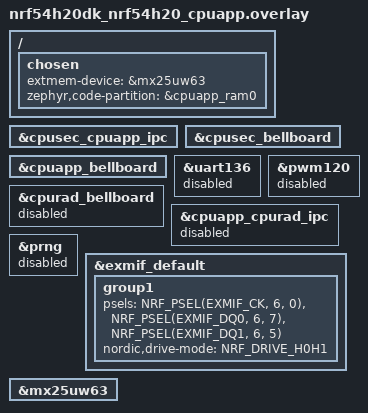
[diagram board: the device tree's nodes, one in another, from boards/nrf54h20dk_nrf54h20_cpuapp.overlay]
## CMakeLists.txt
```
#
# Copyright (c) 2024 Nordic Semiconductor ASA
#
# SPDX-License-Identifier: LicenseRef-Nordic-5-Clause
#

cmake_minimum_required(VERSION 3.20.0)

find_package(Zephyr REQUIRED HINTS $ENV{ZEPHYR_BASE})
project(flash_companion)

target_sources(app PRIVATE src/main.c)
```

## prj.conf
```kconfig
#
# Copyright (c) 2024 Nordic Semiconductor ASA
#
# SPDX-License-Identifier: LicenseRef-Nordic-5-Clause
#

# Minimal scheduler configuration
CONFIG_NUM_PREEMPT_PRIORITIES=0
CONFIG_MULTITHREADING=y
CONFIG_NUM_COOP_PRIORITIES=16
CONFIG_NUM_METAIRQ_PRIORITIES=0
CONFIG_SCHED_SIMPLE=y
CONFIG_WAITQ_SIMPLE=y
CONFIG_TICKLESS_KERNEL=n
CONFIG_SSF_DEVICE_INFO_SERVICE_ENABLED=n

# Enable peripherals needed by the flash companion firmware
CONFIG_GPIO=y
CONFIG_PINCTRL=y
CONFIG_FLASH=y

# Disable unused XIP feature in the MSPI driver
CONFIG_MSPI_XIP=n

# Disable power management
CONFIG_PM=n

# Disable GPD service and NRFS
CONFIG_SOC_NRF54H20_GPD=n
CONFIG_NRFS=n

# Disable unneeded interrupt features
CONFIG_DYNAMIC_INTERRUPTS=n
CONFIG_IRQ_OFFLOAD=n

# Disable memory protection
CONFIG_THREAD_STACK_INFO=n
CONFIG_BUILTIN_STACK_GUARD=n

# Disable unneeded ARM core functionality
CONFIG_ARM_MPU=n
CONFIG_FPU=n

# Disable boot banner
CONFIG_BOOT_BANNER=n
CONFIG_NCS_BOOT_BANNER=n
CONFIG_BOOT_DELAY=0

# Disable serial communication
CONFIG_SERIAL=n
CONFIG_CONSOLE=n
CONFIG_UART_CONSOLE=n
CONFIG_STDOUT_CONSOLE=n
CONFIG_PRINTK=n
CONFIG_EARLY_CONSOLE=n

# Build
CONFIG_SIZE_OPTIMIZATIONS=y

# Enable external memory service
CONFIG_SSF_EXTMEM_SERVICE_ENABLED=y

# Link against zephyr,code-partition
CONFIG_USE_DT_CODE_PARTITION=y

CONFIG_SUIT_LOCAL_ENVELOPE_GENERATE=n
CONFIG_SUIT_ENVELOPE_TARGET=""
CONFIG_NRF_REGTOOL_GENERATE_UICR=n
CONFIG_SOC_NRF54H20_GENERATE_BICR=n

# Enable canonical zcbor encoding
CONFIG_ZCBOR_CANONICAL=y

# Enable LTO
CONFIG_LTO=y
CONFIG_ISR_TABLES_LOCAL_DECLARATION=y

# Minimize flash usage
CONFIG_CLOCK_CONTROL=n

# Set flash base address to zero to ensure that the executable
# code is placed in CPUAPP RAM by the linker.
CONFIG_FLASH_BASE_ADDRESS=0x0
CONFIG_COMMON_LIBC_MALLOC=n
CONFIG_COMMON_LIBC_CALLOC=n
CONFIG_COMMON_LIBC_REALLOCARRAY=n
CONFIG_PICOLIBC_IO_LONG_LONG=n
```

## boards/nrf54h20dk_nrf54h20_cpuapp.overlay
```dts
/*
 * Copyright (c) 2024 Nordic Semiconductor ASA
 *
 * SPDX-License-Identifier: LicenseRef-Nordic-5-Clause
 */

/ {
	chosen {
		extmem-device = &mx25uw63;
		zephyr,code-partition = &cpuapp_ram0;
	};
};

&cpusec_cpuapp_ipc {
	status = "okay";
};

&cpusec_bellboard {
	status = "okay";
};

&cpuapp_bellboard {
	status = "okay";
};

&uart136 {
	status = "disabled";
};

&cpurad_bellboard {
	status = "disabled";
};

&pwm120 {
	status = "disabled";
};

&cpuapp_cpurad_ipc {
	status = "disabled";
};

&prng {
	status = "disabled";
};


&exmif_default {
	group1 {
		psels = <NRF_PSEL(EXMIF_CK, 6, 0)>,
			<NRF_PSEL(EXMIF_DQ0, 6, 7)>,
			<NRF_PSEL(EXMIF_DQ1, 6, 5)>;
		nordic,drive-mode = <NRF_DRIVE_H0H1>;
	};
};

&mx25uw63 {
	status = "okay";
};
```

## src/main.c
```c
/*
 * Copyright (c) 2024 Nordic Semiconductor ASA
 *
 * SPDX-License-Identifier: LicenseRef-Nordic-5-Clause
 */

#include <zephyr/kernel.h>
#include <sdfw/sdfw_services/extmem_remote.h>

int main(void)
{
	extmem_remote_init();
	return 0;
}
```
